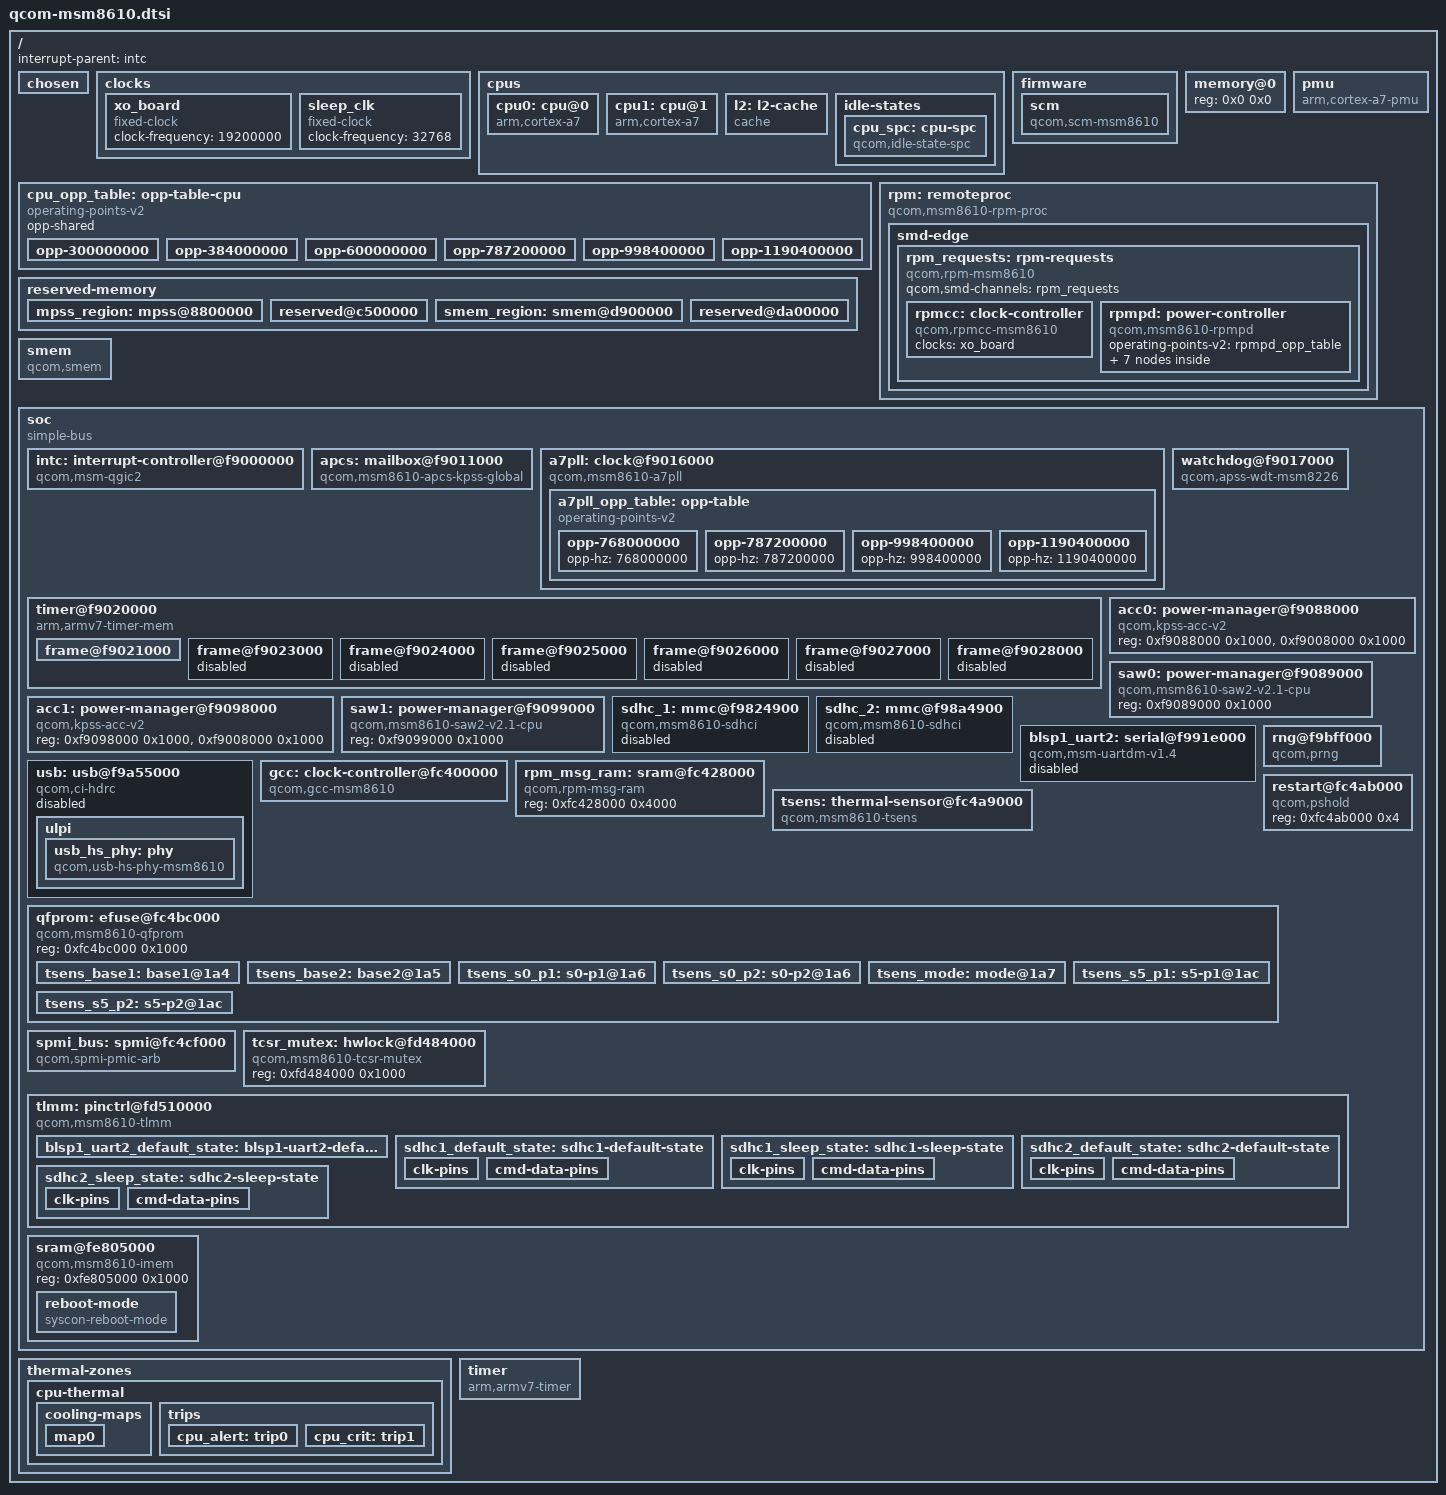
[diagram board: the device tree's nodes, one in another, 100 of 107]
// SPDX-License-Identifier: BSD-3-Clause
/*
 * Qualcomm MSM8610/MSM8210 (Snapdragon 200) SoC device tree source
 */

/dts-v1/;

#include <dt-bindings/interrupt-controller/arm-gic.h>
#include <dt-bindings/clock/qcom,gcc-msm8974.h>
#include <dt-bindings/clock/qcom,rpmcc.h>
#include <dt-bindings/power/qcom-rpmpd.h>
#include <dt-bindings/reset/qcom,gcc-msm8974.h>
#include <dt-bindings/thermal/thermal.h>

/ {
	#address-cells = <1>;
	#size-cells = <1>;
	interrupt-parent = <&intc>;

	chosen { };

	clocks {
		xo_board: xo_board {
			compatible = "fixed-clock";
			#clock-cells = <0>;
			clock-frequency = <19200000>;
		};

		sleep_clk: sleep_clk {
			compatible = "fixed-clock";
			#clock-cells = <0>;
			clock-frequency = <32768>;
		};
	};

	cpus {
		#address-cells = <1>;
		#size-cells = <0>;

		cpu0: cpu@0 {
			compatible = "arm,cortex-a7";
			enable-method = "qcom,msm8610-smp";
			device_type = "cpu";
			reg = <0>;
			clocks = <&apcs>;
			cpu-idle-states = <&cpu_spc>;
			next-level-cache = <&l2>;
			operating-points-v2 = <&cpu_opp_table>;
			qcom,acc = <&acc0>;
			qcom,saw = <&saw0>;
			#cooling-cells = <2>;
		};

		cpu1: cpu@1 {
			compatible = "arm,cortex-a7";
			enable-method = "qcom,msm8610-smp";
			device_type = "cpu";
			reg = <1>;
			clocks = <&apcs>;
			cpu-idle-states = <&cpu_spc>;
			next-level-cache = <&l2>;
			operating-points-v2 = <&cpu_opp_table>;
			qcom,acc = <&acc1>;
			qcom,saw = <&saw1>;
			#cooling-cells = <2>;
		};

		l2: l2-cache {
			compatible = "cache";
			cache-level = <2>;
			cache-unified;
		};

		idle-states {
			cpu_spc: cpu-spc {
				compatible = "qcom,idle-state-spc",
					     "arm,idle-state";
				entry-latency-us = <150>;
				exit-latency-us = <350>;
				min-residency-us = <1200>;
				local-timer-stop;
			};
		};
	};

	firmware {
		scm {
			compatible = "qcom,scm-msm8610", "qcom,scm";
			clocks = <&gcc GCC_CE1_CLK>,
				 <&gcc GCC_CE1_AXI_CLK>,
				 <&gcc GCC_CE1_AHB_CLK>;
			clock-names = "core", "bus", "iface";
		};
	};

	memory@0 {
		device_type = "memory";
		reg = <0x0 0x0>;
	};

	/*
	 * Open-loop voltages: the ceilings of the SVS, nominal and turbo
	 * CPR corners. CPR can lower them further.
	 */
	cpu_opp_table: opp-table-cpu {
		compatible = "operating-points-v2";
		opp-shared;

		opp-300000000 {
			opp-hz = /bits/ 64 <300000000>;
			opp-microvolt = <1150000>;
		};

		opp-384000000 {
			opp-hz = /bits/ 64 <384000000>;
			opp-microvolt = <1150000>;
		};

		opp-600000000 {
			opp-hz = /bits/ 64 <600000000>;
			opp-microvolt = <1150000>;
		};

		opp-787200000 {
			opp-hz = /bits/ 64 <787200000>;
			opp-microvolt = <1150000>;
		};

		opp-998400000 {
			opp-hz = /bits/ 64 <998400000>;
			opp-microvolt = <1275000>;
		};

		opp-1190400000 {
			opp-hz = /bits/ 64 <1190400000>;
			opp-microvolt = <1275000>;
		};
	};


	pmu {
		compatible = "arm,cortex-a7-pmu";
		interrupts = <GIC_PPI 7 (GIC_CPU_MASK_SIMPLE(2) |
					 IRQ_TYPE_LEVEL_HIGH)>;
	};

	rpm: remoteproc {
		compatible = "qcom,msm8610-rpm-proc", "qcom,rpm-proc";

		smd-edge {
			interrupts = <GIC_SPI 168 IRQ_TYPE_EDGE_RISING>;
			mboxes = <&apcs 0>;
			qcom,smd-edge = <15>;

			rpm_requests: rpm-requests {
				compatible = "qcom,rpm-msm8610", "qcom,smd-rpm";
				qcom,smd-channels = "rpm_requests";

				rpmcc: clock-controller {
					compatible = "qcom,rpmcc-msm8610", "qcom,rpmcc";
					#clock-cells = <1>;
					clocks = <&xo_board>;
					clock-names = "xo";
				};

				rpmpd: power-controller {
					compatible = "qcom,msm8610-rpmpd",
						     "qcom,msm8226-rpmpd";
					#power-domain-cells = <1>;
					operating-points-v2 = <&rpmpd_opp_table>;

					rpmpd_opp_table: opp-table {
						compatible = "operating-points-v2";

						rpmpd_opp_ret: opp1 {
							opp-level = <1>;
						};
						rpmpd_opp_svs_krait: opp2 {
							opp-level = <2>;
						};
						rpmpd_opp_svs_soc: opp3 {
							opp-level = <3>;
						};
						rpmpd_opp_nom: opp4 {
							opp-level = <4>;
						};
						rpmpd_opp_turbo: opp5 {
							opp-level = <5>;
						};
						rpmpd_opp_super_turbo: opp6 {
							opp-level = <6>;
						};
					};
				};
			};
		};
	};

	reserved-memory {
		#address-cells = <1>;
		#size-cells = <1>;
		ranges;

		/* Modem and other remote processors, carved out by downstream */
		mpss_region: mpss@8800000 {
			reg = <0x08800000 0x2e00000>;
			no-map;
		};

		/* WCNSS, ADSP, ... */
		reserved@c500000 {
			reg = <0x0c500000 0x1400000>;
			no-map;
		};

		smem_region: smem@d900000 {
			reg = <0x0d900000 0x100000>;
			no-map;
		};

		/* Remote filesystem shared memory, ... */
		reserved@da00000 {
			reg = <0x0da00000 0x400000>;
			no-map;
		};
	};

	smem {
		compatible = "qcom,smem";

		memory-region = <&smem_region>;
		qcom,rpm-msg-ram = <&rpm_msg_ram>;

		hwlocks = <&tcsr_mutex 3>;
	};

	soc: soc {
		compatible = "simple-bus";
		#address-cells = <1>;
		#size-cells = <1>;
		ranges;

		intc: interrupt-controller@f9000000 {
			compatible = "qcom,msm-qgic2";
			reg = <0xf9000000 0x1000>,
			      <0xf9002000 0x1000>;
			interrupt-controller;
			#interrupt-cells = <3>;
		};

		apcs: mailbox@f9011000 {
			compatible = "qcom,msm8610-apcs-kpss-global",
				     "qcom,msm8916-apcs-kpss-global", "syscon";
			reg = <0xf9011000 0x1000>;
			#mbox-cells = <1>;
			clocks = <&a7pll>, <&gcc GPLL0_VOTE>;
			clock-names = "pll", "aux";
			#clock-cells = <0>;
		};

		a7pll: clock@f9016000 {
			compatible = "qcom,msm8610-a7pll", "qcom,msm8226-a7pll";
			reg = <0xf9016000 0x40>;
			#clock-cells = <0>;
			clocks = <&xo_board>;
			clock-names = "xo";
			operating-points-v2 = <&a7pll_opp_table>;

			a7pll_opp_table: opp-table {
				compatible = "operating-points-v2";

				opp-768000000 {
					opp-hz = /bits/ 64 <768000000>;
				};

				opp-787200000 {
					opp-hz = /bits/ 64 <787200000>;
				};

				opp-998400000 {
					opp-hz = /bits/ 64 <998400000>;
				};

				opp-1190400000 {
					opp-hz = /bits/ 64 <1190400000>;
				};
			};
		};

		watchdog@f9017000 {
			compatible = "qcom,apss-wdt-msm8226", "qcom,kpss-wdt";
			reg = <0xf9017000 0x1000>;
			interrupts = <GIC_SPI 3 IRQ_TYPE_EDGE_RISING>,
				     <GIC_SPI 4 IRQ_TYPE_EDGE_RISING>;
			clocks = <&sleep_clk>;
		};

		timer@f9020000 {
			compatible = "arm,armv7-timer-mem";
			reg = <0xf9020000 0x1000>;
			clock-frequency = <19200000>;
			#address-cells = <1>;
			#size-cells = <1>;
			ranges;

			frame@f9021000 {
				frame-number = <0>;
				interrupts = <GIC_SPI 8 IRQ_TYPE_LEVEL_HIGH>,
					     <GIC_SPI 7 IRQ_TYPE_LEVEL_HIGH>;
				reg = <0xf9021000 0x1000>,
				      <0xf9022000 0x1000>;
			};

			frame@f9023000 {
				frame-number = <1>;
				interrupts = <GIC_SPI 9 IRQ_TYPE_LEVEL_HIGH>;
				reg = <0xf9023000 0x1000>;
				status = "disabled";
			};

			frame@f9024000 {
				frame-number = <2>;
				interrupts = <GIC_SPI 10 IRQ_TYPE_LEVEL_HIGH>;
				reg = <0xf9024000 0x1000>;
				status = "disabled";
			};

			frame@f9025000 {
				frame-number = <3>;
				interrupts = <GIC_SPI 11 IRQ_TYPE_LEVEL_HIGH>;
				reg = <0xf9025000 0x1000>;
				status = "disabled";
			};

			frame@f9026000 {
				frame-number = <4>;
				interrupts = <GIC_SPI 12 IRQ_TYPE_LEVEL_HIGH>;
				reg = <0xf9026000 0x1000>;
				status = "disabled";
			};

			frame@f9027000 {
				frame-number = <5>;
				interrupts = <GIC_SPI 13 IRQ_TYPE_LEVEL_HIGH>;
				reg = <0xf9027000 0x1000>;
				status = "disabled";
			};

			frame@f9028000 {
				frame-number = <6>;
				interrupts = <GIC_SPI 14 IRQ_TYPE_LEVEL_HIGH>;
				reg = <0xf9028000 0x1000>;
				status = "disabled";
			};
		};

		acc0: power-manager@f9088000 {
			compatible = "qcom,kpss-acc-v2";
			reg = <0xf9088000 0x1000>, <0xf9008000 0x1000>;
		};

		saw0: power-manager@f9089000 {
			compatible = "qcom,msm8610-saw2-v2.1-cpu", "qcom,saw2";
			reg = <0xf9089000 0x1000>;
		};

		acc1: power-manager@f9098000 {
			compatible = "qcom,kpss-acc-v2";
			reg = <0xf9098000 0x1000>, <0xf9008000 0x1000>;
		};

		saw1: power-manager@f9099000 {
			compatible = "qcom,msm8610-saw2-v2.1-cpu", "qcom,saw2";
			reg = <0xf9099000 0x1000>;
		};

		sdhc_1: mmc@f9824900 {
			compatible = "qcom,msm8610-sdhci", "qcom,sdhci-msm-v4";
			reg = <0xf9824900 0x11c>, <0xf9824000 0x800>;
			reg-names = "hc", "core";
			interrupts = <GIC_SPI 123 IRQ_TYPE_LEVEL_HIGH>,
				     <GIC_SPI 138 IRQ_TYPE_LEVEL_HIGH>;
			interrupt-names = "hc_irq", "pwr_irq";
			clocks = <&gcc GCC_SDCC1_AHB_CLK>,
				 <&gcc GCC_SDCC1_APPS_CLK>,
				 <&xo_board>;
			clock-names = "iface", "core", "xo";
			pinctrl-0 = <&sdhc1_default_state>;
			pinctrl-1 = <&sdhc1_sleep_state>;
			pinctrl-names = "default", "sleep";
			bus-width = <8>;
			non-removable;
			status = "disabled";
		};

		sdhc_2: mmc@f98a4900 {
			compatible = "qcom,msm8610-sdhci", "qcom,sdhci-msm-v4";
			reg = <0xf98a4900 0x11c>, <0xf98a4000 0x800>;
			reg-names = "hc", "core";
			interrupts = <GIC_SPI 125 IRQ_TYPE_LEVEL_HIGH>,
				     <GIC_SPI 221 IRQ_TYPE_LEVEL_HIGH>;
			interrupt-names = "hc_irq", "pwr_irq";
			clocks = <&gcc GCC_SDCC2_AHB_CLK>,
				 <&gcc GCC_SDCC2_APPS_CLK>,
				 <&xo_board>;
			clock-names = "iface", "core", "xo";
			pinctrl-0 = <&sdhc2_default_state>;
			pinctrl-1 = <&sdhc2_sleep_state>;
			pinctrl-names = "default", "sleep";
			bus-width = <4>;
			status = "disabled";
		};

		blsp1_uart2: serial@f991e000 {
			compatible = "qcom,msm-uartdm-v1.4", "qcom,msm-uartdm";
			reg = <0xf991e000 0x1000>;
			interrupts = <GIC_SPI 108 IRQ_TYPE_LEVEL_HIGH>;
			clocks = <&gcc GCC_BLSP1_UART2_APPS_CLK>,
				 <&gcc GCC_BLSP1_AHB_CLK>;
			clock-names = "core", "iface";
			pinctrl-0 = <&blsp1_uart2_default_state>;
			pinctrl-names = "default";
			status = "disabled";
		};

		usb: usb@f9a55000 {
			compatible = "qcom,ci-hdrc";
			reg = <0xf9a55000 0x200>,
			      <0xf9a55200 0x200>;
			interrupts = <GIC_SPI 134 IRQ_TYPE_LEVEL_HIGH>;
			clocks = <&gcc GCC_USB_HS_AHB_CLK>,
				 <&gcc GCC_USB_HS_SYSTEM_CLK>;
			clock-names = "iface", "core";
			assigned-clocks = <&gcc GCC_USB_HS_SYSTEM_CLK>;
			assigned-clock-rates = <75000000>;
			resets = <&gcc GCC_USB_HS_BCR>;
			reset-names = "core";
			phy_type = "ulpi";
			dr_mode = "otg";
			hnp-disable;
			srp-disable;
			adp-disable;
			ahb-burst-config = <0>;
			phy-names = "usb-phy";
			phys = <&usb_hs_phy>;
			status = "disabled";
			#reset-cells = <1>;

			ulpi {
				usb_hs_phy: phy {
					compatible = "qcom,usb-hs-phy-msm8610",
						     "qcom,usb-hs-phy";
					#phy-cells = <0>;
					clocks = <&xo_board>,
						 <&gcc GCC_USB2A_PHY_SLEEP_CLK>;
					clock-names = "ref", "sleep";
					resets = <&gcc GCC_USB2A_PHY_BCR>, <&usb 0>;
					reset-names = "phy", "por";
					qcom,init-seq = /bits/ 8 <0x0 0x44
						0x1 0x68 0x2 0x24 0x3 0x13>;
				};
			};
		};

		rng@f9bff000 {
			compatible = "qcom,prng";
			reg = <0xf9bff000 0x200>;
			clocks = <&gcc GCC_PRNG_AHB_CLK>;
			clock-names = "core";
		};

		gcc: clock-controller@fc400000 {
			compatible = "qcom,gcc-msm8610";
			reg = <0xfc400000 0x4000>;
			#clock-cells = <1>;
			#reset-cells = <1>;
			#power-domain-cells = <1>;

			clocks = <&xo_board>,
				 <&sleep_clk>;
			clock-names = "xo",
				      "sleep_clk";
		};

		rpm_msg_ram: sram@fc428000 {
			compatible = "qcom,rpm-msg-ram";
			reg = <0xfc428000 0x4000>;
		};

		tsens: thermal-sensor@fc4a9000 {
			compatible = "qcom,msm8610-tsens", "qcom,tsens-v0_1";
			reg = <0xfc4a9000 0x1000>, /* TM */
			      <0xfc4a8000 0x1000>; /* SROT */
			nvmem-cells = <&tsens_mode>,
				      <&tsens_base1>, <&tsens_base2>,
				      <&tsens_s0_p1>, <&tsens_s0_p2>,
				      <&tsens_s5_p1>, <&tsens_s5_p2>;
			nvmem-cell-names = "mode",
					   "base1", "base2",
					   "s0_p1", "s0_p2",
					   "s5_p1", "s5_p2";
			#qcom,sensors = <2>;
			interrupts = <GIC_SPI 184 IRQ_TYPE_LEVEL_HIGH>;
			interrupt-names = "uplow";
			#thermal-sensor-cells = <1>;
		};

		restart@fc4ab000 {
			compatible = "qcom,pshold";
			reg = <0xfc4ab000 0x4>;
		};

		qfprom: efuse@fc4bc000 {
			compatible = "qcom,msm8610-qfprom", "qcom,qfprom";
			reg = <0xfc4bc000 0x1000>;
			#address-cells = <1>;
			#size-cells = <1>;

			tsens_base1: base1@1a4 {
				reg = <0x1a4 0x1>;
				bits = <0 8>;
			};

			tsens_base2: base2@1a5 {
				reg = <0x1a5 0x1>;
				bits = <0 8>;
			};

			tsens_s0_p1: s0-p1@1a6 {
				reg = <0x1a6 0x1>;
				bits = <0 6>;
			};

			tsens_s0_p2: s0-p2@1a6 {
				reg = <0x1a6 0x2>;
				bits = <6 6>;
			};

			tsens_mode: mode@1a7 {
				reg = <0x1a7 0x1>;
				bits = <4 3>;
			};

			tsens_s5_p1: s5-p1@1ac {
				reg = <0x1ac 0x1>;
				bits = <0 6>;
			};

			tsens_s5_p2: s5-p2@1ac {
				reg = <0x1ac 0x2>;
				bits = <6 6>;
			};
		};

		spmi_bus: spmi@fc4cf000 {
			compatible = "qcom,spmi-pmic-arb";
			reg-names = "core", "intr", "cnfg";
			reg = <0xfc4cf000 0x1000>,
			      <0xfc4cb000 0x1000>,
			      <0xfc4ca000 0x1000>;
			interrupt-names = "periph_irq";
			interrupts = <GIC_SPI 190 IRQ_TYPE_LEVEL_HIGH>;
			qcom,ee = <0>;
			qcom,channel = <0>;
			#address-cells = <2>;
			#size-cells = <0>;
			interrupt-controller;
			#interrupt-cells = <4>;
		};

		tcsr_mutex: hwlock@fd484000 {
			compatible = "qcom,msm8610-tcsr-mutex", "qcom,tcsr-mutex";
			reg = <0xfd484000 0x1000>;
			#hwlock-cells = <1>;
		};

		tlmm: pinctrl@fd510000 {
			compatible = "qcom,msm8610-tlmm";
			reg = <0xfd510000 0x4000>;
			interrupts = <GIC_SPI 208 IRQ_TYPE_LEVEL_HIGH>;
			gpio-controller;
			#gpio-cells = <2>;
			gpio-ranges = <&tlmm 0 0 102>;
			interrupt-controller;
			#interrupt-cells = <2>;

			blsp1_uart2_default_state: blsp1-uart2-default-state {
				pins = "gpio4", "gpio5";
				function = "blsp_uart2";
				drive-strength = <8>;
				bias-disable;
			};

			sdhc1_default_state: sdhc1-default-state {
				clk-pins {
					pins = "sdc1_clk";
					drive-strength = <10>;
					bias-disable;
				};

				cmd-data-pins {
					pins = "sdc1_cmd", "sdc1_data";
					drive-strength = <10>;
					bias-pull-up;
				};
			};

			sdhc1_sleep_state: sdhc1-sleep-state {
				clk-pins {
					pins = "sdc1_clk";
					drive-strength = <2>;
					bias-disable;
				};

				cmd-data-pins {
					pins = "sdc1_cmd", "sdc1_data";
					drive-strength = <2>;
					bias-pull-up;
				};
			};

			sdhc2_default_state: sdhc2-default-state {
				clk-pins {
					pins = "sdc2_clk";
					drive-strength = <10>;
					bias-disable;
				};

				cmd-data-pins {
					pins = "sdc2_cmd", "sdc2_data";
					drive-strength = <10>;
					bias-pull-up;
				};
			};

			sdhc2_sleep_state: sdhc2-sleep-state {
				clk-pins {
					pins = "sdc2_clk";
					drive-strength = <2>;
					bias-disable;
				};

				cmd-data-pins {
					pins = "sdc2_cmd", "sdc2_data";
					drive-strength = <2>;
					bias-pull-up;
				};
			};
		};

		sram@fe805000 {
			compatible = "qcom,msm8610-imem", "syscon", "simple-mfd";
			reg = <0xfe805000 0x1000>;

			reboot-mode {
				compatible = "syscon-reboot-mode";
				offset = <0x65c>;

				mode-bootloader = <0x77665500>;
				mode-normal = <0x77665501>;
				mode-recovery = <0x77665502>;
			};
		};
	};

	thermal-zones {
		cpu-thermal {
			polling-delay-passive = <250>;
			polling-delay = <1000>;

			thermal-sensors = <&tsens 5>;

			cooling-maps {
				map0 {
					trip = <&cpu_alert>;
					cooling-device = <&cpu0 THERMAL_NO_LIMIT THERMAL_NO_LIMIT>,
							 <&cpu1 THERMAL_NO_LIMIT THERMAL_NO_LIMIT>;
				};
			};

			trips {
				cpu_alert: trip0 {
					temperature = <75000>;
					hysteresis = <2000>;
					type = "passive";
				};

				cpu_crit: trip1 {
					temperature = <110000>;
					hysteresis = <2000>;
					type = "critical";
				};
			};
		};
	};

	timer {
		compatible = "arm,armv7-timer";
		interrupts = <GIC_PPI 2
				(GIC_CPU_MASK_SIMPLE(2) | IRQ_TYPE_LEVEL_LOW)>,
			     <GIC_PPI 3
				(GIC_CPU_MASK_SIMPLE(2) | IRQ_TYPE_LEVEL_LOW)>,
			     <GIC_PPI 4
				(GIC_CPU_MASK_SIMPLE(2) | IRQ_TYPE_LEVEL_LOW)>,
			     <GIC_PPI 1
				(GIC_CPU_MASK_SIMPLE(2) | IRQ_TYPE_LEVEL_LOW)>;
		clock-frequency = <19200000>;
	};
};
